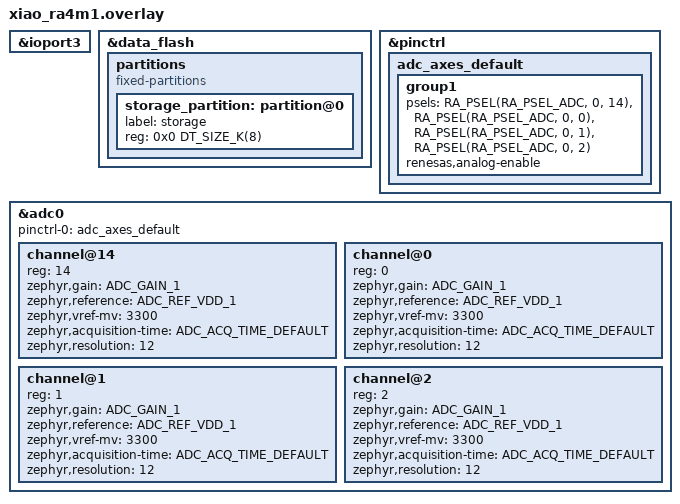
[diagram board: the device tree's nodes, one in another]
&ioport3 {
    status = "okay";
};

&data_flash {
    partitions {
        compatible = "fixed-partitions";
        #address-cells = <1>;
        #size-cells = <1>;

        storage_partition: partition@0 {
            label = "storage";
            reg = <0x0 DT_SIZE_K(8)>;
        };
    };
};

&pinctrl {
    adc_axes_default: adc_axes_default {
        group1 {
            psels = <RA_PSEL(RA_PSEL_ADC, 0, 14)>, /* D0 */
                <RA_PSEL(RA_PSEL_ADC, 0, 0)>, /* D1 */
                <RA_PSEL(RA_PSEL_ADC, 0, 1)>, /* D2 */
                <RA_PSEL(RA_PSEL_ADC, 0, 2)>; /* D3 */
            renesas,analog-enable;
        };
    };
};

&adc0 {
    pinctrl-0 = <&adc_axes_default>;
    pinctrl-names = "default";

    status = "okay";
    #address-cells = <1>;
    #size-cells = <0>;

    channel@14 {
        reg = <14>; /* D0, P014 */
        zephyr,gain = "ADC_GAIN_1";
        zephyr,reference = "ADC_REF_VDD_1";
        zephyr,vref-mv = <3300>;
        zephyr,acquisition-time = <ADC_ACQ_TIME_DEFAULT>;
        zephyr,resolution = <12>;
    };

    channel@0 {
        reg = <0>; /* D1, P000 */
        zephyr,gain = "ADC_GAIN_1";
        zephyr,reference = "ADC_REF_VDD_1";
        zephyr,vref-mv = <3300>;
        zephyr,acquisition-time = <ADC_ACQ_TIME_DEFAULT>;
        zephyr,resolution = <12>;
    };

    channel@1 {
        reg = <1>; /* D2, P001 */
        zephyr,gain = "ADC_GAIN_1";
        zephyr,reference = "ADC_REF_VDD_1";
        zephyr,vref-mv = <3300>;
        zephyr,acquisition-time = <ADC_ACQ_TIME_DEFAULT>;
        zephyr,resolution = <12>;
    };

    channel@2 {
        reg = <2>; /* D3, P002 */
        zephyr,gain = "ADC_GAIN_1";
        zephyr,reference = "ADC_REF_VDD_1";
        zephyr,vref-mv = <3300>;
        zephyr,acquisition-time = <ADC_ACQ_TIME_DEFAULT>;
        zephyr,resolution = <12>;
    };
};
